# csrng: IP-XACT component
VLNV tenstorrent.com:ocah:csrng:1.0

## Address spaces and blocks
csrng_mmap.csrng: base 'h0, range 'h60, width 32

## Registers
Registers are 32-bit, read-write, reset 0x0 unless marked. A register's access mark holds for its fields unless they carry their own. Offsets are from the block's base; lines under a group give offsets from that group; [hi:lo] are bit positions; {n}, {i} and the like mark numbered series; 'fields as' and 'values as' point back to an identical list; <NAME> marks a mode.

## csrng_mmap.csrng — Takes entropy bits to produce cryptographically secure random numbers for consumption by hardware blocks and by software
Base 0x00000000
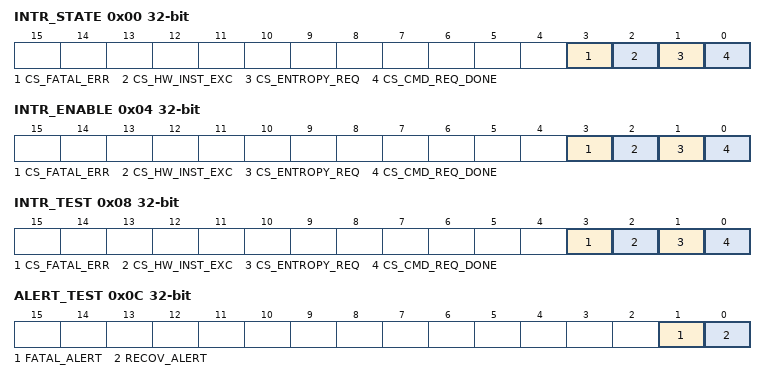
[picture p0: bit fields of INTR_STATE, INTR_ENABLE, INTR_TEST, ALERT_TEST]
0x00 INTR_STATE
  [3] CS_FATAL_ERR write-1-clears — Asserted when a FIFO error or a fatal alert occurs. Check the !!ERR_CODE register to get more information.
  [2] CS_HW_INST_EXC write-1-clears — Asserted when a hardware-attached CSRNG instance encounters a command exception
  [1] CS_ENTROPY_REQ write-1-clears — Asserted when a request for entropy has been made.
  [0] CS_CMD_REQ_DONE write-1-clears — Asserted when a command request is completed.
0x04 INTR_ENABLE
  [3] CS_FATAL_ERR — Enable interrupt when !!INTR_STATE.cs_fatal_err is set.
  [2] CS_HW_INST_EXC — Enable interrupt when !!INTR_STATE.cs_hw_inst_exc is set.
  [1] CS_ENTROPY_REQ — Enable interrupt when !!INTR_STATE.cs_entropy_req is set.
  [0] CS_CMD_REQ_DONE — Enable interrupt when !!INTR_STATE.cs_cmd_req_done is set.
0x08 INTR_TEST wo
  [3] CS_FATAL_ERR — Write 1 to force !!INTR_STATE.cs_fatal_err to 1.
  [2] CS_HW_INST_EXC — Write 1 to force !!INTR_STATE.cs_hw_inst_exc to 1.
  [1] CS_ENTROPY_REQ — Write 1 to force !!INTR_STATE.cs_entropy_req to 1.
  [0] CS_CMD_REQ_DONE — Write 1 to force !!INTR_STATE.cs_cmd_req_done to 1.
0x0C ALERT_TEST wo
  [1] FATAL_ALERT — Write 1 to trigger one alert event of this kind.
  [0] RECOV_ALERT — Write 1 to trigger one alert event of this kind.
0x10 REGWEN reset 0x1
  [0] REGWEN write-0-clears — When true, all writeable registers can be modified. When false, they become read-only.
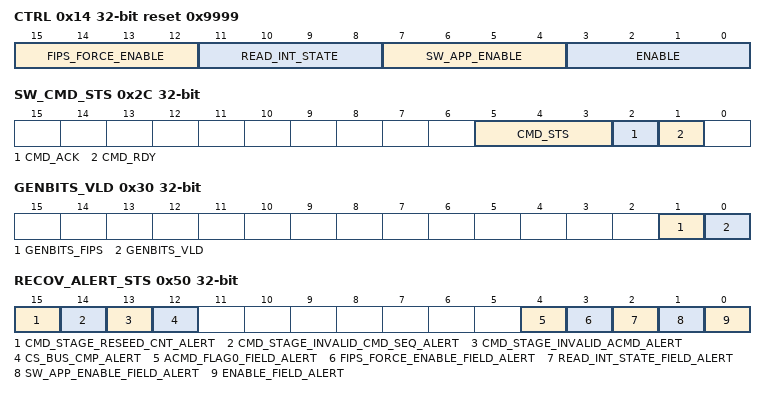
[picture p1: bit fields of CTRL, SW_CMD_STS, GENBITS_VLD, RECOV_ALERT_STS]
0x14 CTRL reset 0x9999
  [all] fields
    6=True; 9=False
  [15:12] FIPS_FORCE_ENABLE — Setting this field to kMultiBitBool4True enables forcing the FIPS/CC compliance flag to true via the !!FIPS_FORCE register.
  [11:8] READ_INT_STATE — Setting this field to kMultiBitBool4True will enable reading from the !!INT_STATE_VAL register. Reading the internal state of the enable instances will be enabled only if the otp_en_csrng_sw_app_read input vector is set to the enable encoding. Also, the !!INT_STATE_READ_ENABLE bit of the selected instance needs to be set to true for this to work.
  [7:4] SW_APP_ENABLE — Setting this field to kMultiBitBool4True will enable reading from the !!GENBITS register. This application interface for software (register based) will be enabled only if the otp_en_csrng_sw_app_read input vector is set to the enable encoding.
  [3:0] ENABLE — Setting this field to kMultiBitBool4True will enable the CSRNG module. The modules of the entropy complex may only be enabled and disabled in a specific order, see Programmers Guide for details.
0x18 CMD_REQ wo
  [31:0] CMD_REQ — Writing this request with defined CSRNG commands will initiate all possible CSRNG actions. The application interface must wait for the "ack" to return before issuing new commands.
0x1C RESEED_INTERVAL reset 0xFFFFFFFF
  [31:0] RESEED_INTERVAL — Setting this field will set the number of generate requests that can be made to CSRNG before a reseed request needs to be made. This register supports a maximum of 2^32 requests between reseeds. This register will be compared to a counter, which counts the number of generate commands between reseed or instantiate commands. If the counter reaches the value of this register, the violating command will be acknowledged with a status error. If the violating command was issued by a HW instance, an interrupt will be triggered.
0x20 RESEED_COUNTER_0 ro
  [31:0] RESEED_COUNTER_0 — Reseed Counter indicating the number of completed Generate requests since the last Instantiate or Reseed command.
0x24 RESEED_COUNTER_1 ro
  [31:0] RESEED_COUNTER_0 — For RESEED_COUNTER1
0x28 RESEED_COUNTER_2 ro
  [31:0] RESEED_COUNTER_0 — For RESEED_COUNTER2
0x2C SW_CMD_STS ro
  [5:3] CMD_STS — This field represents the status code returned with the application command ack. It is updated each time a command ack is asserted on the internal application interface for software use. To check whether a command was successful, wait for !!INTR_STATE.CS_CMD_REQ_DONE or !!SW_CMD_STS.CMD_ACK to be high and then check the value of this field.
  [2] CMD_ACK — This one bit field indicates when a SW command has been acknowledged by the CSRNG. It is set to low each time a new command is written to !!CMD_REQ. The field is set to high once a SW command request has been acknowledged by the CSRNG. 0b0: The last SW command has not been acknowledged yet. 0b1: The last SW command has been acknowledged. In case of a generate command the acknowledgement goes high after all of the requested entropy is consumed.
  [1] CMD_RDY — This bit indicates when the command interface is ready to accept commands. Before starting to write a new command to !!SW_CMD_REQ, this field needs to be polled. 0b0: CSRNG is not ready to accept commands or the last command hasn't been acked yet. 0b1: CSRNG is ready to accept the next command.
0x30 GENBITS_VLD ro reset not defined
  [1] GENBITS_FIPS — This bit is set when genbits are FIPS/CC compliant.
  [0] GENBITS_VLD — This bit is set when genbits are available on this application interface after a generate command has been issued.
0x34 GENBITS ro reset not defined
  [31:0] GENBITS — Reading this register will get the generated bits that were requested with the generate request. This register must be read four times for each request made. For example, an application command generate request with a `clen` value of 4 requires this register to be read 16 times to get all of the data out of the FIFO path. Note that for !!GENBITS to be able to deliver random numbers, also !!CTRL.SW_APP_ENABLE needs to be set to `kMultiBitBool4True`. In addition, the otp_en_csrng_sw_app_read input needs to be set to `kMultiBitBool8True`. Otherwise, the register reads as 0.
0x38 INT_STATE_READ_ENABLE reset 0x7
  [2:0] INT_STATE_READ_ENABLE — Per-instance internal state read enable. Defines whether the internal state of the corresponding instance is readable via !!INT_STATE_VAL. Note that for !!INT_STATE_VAL to provide read access to the internal state, also !!CTRL.READ_INT_STATE needs to be set to `kMultiBitBool4True`. In addition, the otp_en_csrng_sw_app_read input needs to be set to `kMultiBitBool8True`.
0x3C INT_STATE_READ_ENABLE_REGWEN reset 0x1
  [0] INT_STATE_READ_ENABLE_REGWEN write-0-clears — INT_STATE_READ_ENABLE register configuration enable bit. If this is cleared to 0, the INT_STATE_READ_ENABLE register cannot be written anymore.
0x40 INT_STATE_NUM
  [3:0] INT_STATE_NUM — Setting this field will set the number for which internal state can be selected for a read access. Up to 16 internal state values can be chosen from this register. The actual number of valid internal state fields is set by parameter NumHwApps plus 1 software app. For those selections that point to reserved locations (greater than NumHwApps plus 1), the returned value will be zero. Writing this register will also reset the internal read pointer for the !!INT_STATE_VAL register. Note: This register should be read back after being written to ensure that the !!INT_STATE_VAL read back is accurate.
0x44 INT_STATE_VAL ro reset not defined
  [31:0] INT_STATE_VAL — Reading this register will dump out the contents of the selected internal state field. Since the internal state field is 448 bits wide, it will require 14 reads from this register to gather the entire field. Once 14 reads have been done, the internal read pointer (selects 32 bits of the 448 bit field) will reset to zero. The !!INT_STATE_NUM can be re-written at this time (internal read pointer is also reset), and then another internal state field can be read. Note that for !!INT_STATE_VAL to provide read access to the internal state, also !!CTRL.READ_INT_STATE needs to be set to `kMultiBitBool4True`. In addition, the otp_en_csrng_sw_app_read input needs to be set to `kMultiBitBool8True`. Also, the !!INT_STATE_READ_ENABLE bit of the selected instance needs to be set to true for this to work. Otherwise, the register reads as 0.
0x48 FIPS_FORCE
  [2:0] FIPS_FORCE — Force the FIPS/CC compliance flag of individual instances to true. This allows CSRNG to set the output FIPS/CC compliance flag to true despite running in fully deterministic mode (flag0 being true). This can be useful e.g. for known-answer testing through entropy consumers accepting FIPS/CC compliant entropy only, or when firmware is used to derive FIPS/CC compliant entropy seeds. After setting a particular bit to 1, the FIPS/CC compliance flag of the corresponding instance will be forced to true upon the next Instantiate or Reseed command. Note that for this to work, !!CTRL.FIPS_FORCE_ENABLE needs to be set to kMultiBitBool4True.
0x4C HW_EXC_STS
  [15:0] HW_EXC_STS write-0-clears — Reading this register indicates whether one of the CSRNG HW instances has encountered an exception. Each bit corresponds to a particular hardware instance, with bit 0 corresponding to instance HW0, bit 1 corresponding to instance HW1, and so forth. (To monitor the status of requests made to the SW instance, check the !!SW_CMD_STS register). Writing a zero to this register resets the status bits.
0x50 RECOV_ALERT_STS
  [15] CMD_STAGE_RESEED_CNT_ALERT write-0-clears — This bit is set when the maximum number of generate requests between reseeds is exceeded. The invalid generate command is ignored and CSRNG continues to operate. Writing a zero resets this status bit.
  [14] CMD_STAGE_INVALID_CMD_SEQ_ALERT write-0-clears — This bit is set when an out of order command is received by the main state machine. This happens when an instantiate command is sent for a state that was already instantiated or when any command other than instantiate is sent for a state that wasn't instantiated yet. The invalid command is ignored and CSRNG continues to operate. Writing a zero resets this status bit.
  [13] CMD_STAGE_INVALID_ACMD_ALERT write-0-clears — This bit is set when an unsupported/illegal CSRNG command is received by the main state machine. The invalid command is ignored and CSRNG continues to operate. Writing a zero resets this status bit.
  [12] CS_BUS_CMP_ALERT write-0-clears — This bit is set when the software application port genbits bus value is equal to the prior valid value on the bus, indicating a possible attack. Writing a zero resets this status bit.
  [4] ACMD_FLAG0_FIELD_ALERT write-0-clears — This bit is set when the FLAG0 field in the Application Command is set to a value other than kMultiBitBool4True or kMultiBitBool4False. Writing a zero resets this status bit.
  [3] FIPS_FORCE_ENABLE_FIELD_ALERT write-0-clears — This bit is set when the FIPS_FORCE_ENABLE field in the !!CTRL register is set to a value other than kMultiBitBool4True or kMultiBitBool4False. Writing a zero resets this status bit.
  [2] READ_INT_STATE_FIELD_ALERT write-0-clears — This bit is set when the READ_INT_STATE field in the !!CTRL register is set to a value other than kMultiBitBool4True or kMultiBitBool4False. Writing a zero resets this status bit.
  [1] SW_APP_ENABLE_FIELD_ALERT write-0-clears — This bit is set when the SW_APP_ENABLE field in the !!CTRL register is set to a value other than kMultiBitBool4True or kMultiBitBool4False. Writing a zero resets this status bit.
  [0] ENABLE_FIELD_ALERT write-0-clears — This bit is set when the ENABLE field in the !!CTRL register is set to a value other than kMultiBitBool4True or kMultiBitBool4False. Writing a zero resets this status bit.
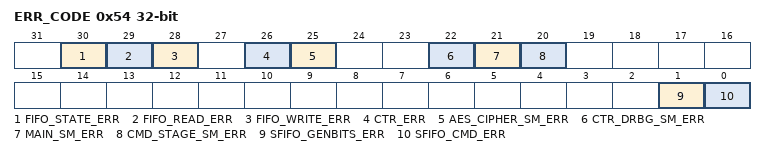
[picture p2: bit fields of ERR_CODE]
0x54 ERR_CODE ro
  [30] FIFO_STATE_ERR — This bit will be set to one when any of the source bits (bits 0 through 15 of this this register) are asserted as a result of an error pulse generated from any FIFO where both the empty and full status bits are set. This bit will stay set until the next reset.
  [29] FIFO_READ_ERR — This bit will be set to one when any of the source bits (bits 0 through 15 of this this register) are asserted as a result of an error pulse generated from any empty FIFO that has received a read pulse. This bit will stay set until the next reset.
  [28] FIFO_WRITE_ERR — This bit will be set to one when any of the source bits (bits 0 through 15 of this this register) are asserted as a result of an error pulse generated from any full FIFO that has been received a write pulse. This bit will stay set until the next reset.
  [26] CTR_ERR — This bit will be set to one when a mismatch in any of the hardened counters has been detected. This error will signal a fatal alert, and also an interrupt if enabled. This bit will stay set until the next reset.
  [25] AES_CIPHER_SM_ERR — This bit will be set to one when an AES fatal error has been detected. This error will signal a fatal alert, and also an interrupt if enabled. This bit will stay set until the next reset.
  [22] CTR_DRBG_SM_ERR — This bit will be set to one when an illegal state has been detected for the ctr_drbg state machine. This error will signal a fatal alert, and also an interrupt if enabled. This bit will stay set until the next reset.
  [21] MAIN_SM_ERR — This bit will be set to one when an illegal state has been detected for the main state machine. This error will signal a fatal alert, and also an interrupt if enabled. This bit will stay set until the next reset.
  [20] CMD_STAGE_SM_ERR — This bit will be set to one when an illegal state has been detected for the command stage state machine. This error will signal a fatal alert, and also an interrupt if enabled. This bit will stay set until the next reset.
  [1] SFIFO_GENBITS_ERR — This bit will be set to one when an error has been detected for the command stage genbits FIFO. The type of error is reflected in the type status bits (bits 28 through 30 of this register). This bit will stay set until the next reset.
  [0] SFIFO_CMD_ERR — This bit will be set to one when an error has been detected for the command stage command FIFO. The type of error is reflected in the type status bits (bits 28 through 30 of this register). This bit will stay set until the next reset.
0x58 ERR_CODE_TEST
  [4:0] ERR_CODE_TEST — Setting this field will set the bit number for which an error will be forced in the hardware. This bit number is that same one found in the !!ERR_CODE register. The action of writing this register will force an error pulse. The sole purpose of this register is to test that any error properly propagates to either an interrupt or an alert.
0x5C MAIN_SM_STATE ro reset 0x37
  [5:0] MAIN_SM_STATE — This is the state of the CSRNG main state machine. See the RTL file `csrng_main_sm` for the meaning of the values.

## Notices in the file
SPDX-License-Identifier: Apache-2.0
SPDX-FileCopyrightText: 2026 Tenstorrent USA, Inc.
